# SA3_SS_SA_UL_0_SA_UL_UPDATES_40901000h register map
Vendor: Texas Instruments
Peripheral module from a debugger description file (folder AM275x).
Registers are 32-bit, write-only, reset 0x0 unless marked. A register's access mark holds for its fields unless they carry their own. Offsets are as the file gives them; lines under a group give offsets from that group; [hi:lo] are bit positions; {n}, {i} and the like mark numbered series; 'fields as' and 'values as' point back to an identical list; <NAME> marks a mode.

## sa_ul_updates
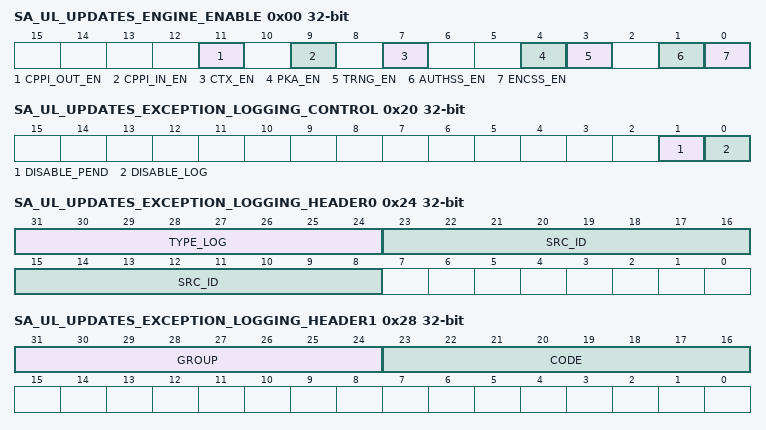
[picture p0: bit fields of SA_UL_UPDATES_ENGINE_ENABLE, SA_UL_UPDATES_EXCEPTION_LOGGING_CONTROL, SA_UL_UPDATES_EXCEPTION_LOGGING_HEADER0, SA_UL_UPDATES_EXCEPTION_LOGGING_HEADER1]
0x00 SA_UL_UPDATES_ENGINE_ENABLE rw — This register controls the enable of each crypto engine
  [11] CPPI_OUT_EN — cppi out enable Reset Source: rst_mod_g_rst_n
  [9] CPPI_IN_EN — cppi in enable Reset Source: rst_mod_g_rst_n
  [7] CTX_EN — ctxcach enable Reset Source: rst_mod_g_rst_n
  [4] PKA_EN — pka enable Reset Source: rst_mod_g_rst_n
  [3] TRNG_EN — trng enable Reset Source: rst_mod_g_rst_n
  [1] AUTHSS_EN — authss enable Reset Source: rst_mod_g_rst_n
  [0] ENCSS_EN — encss enable Reset Source: rst_mod_g_rst_n
0x10 SA_UL_UPDATES_SCPTR_PROMOTE_LOW_RANGE_L rw — This register contains bit 31:0 of the SCPTR lower limit for promotion check
  [31:0] BIT_31_0 — The lower 32-bits of SCPTR lower limit Reset Source: rst_mod_g_rst_n
0x14 SA_UL_UPDATES_SCPTR_PROMOTE_LOW_RANGE_H rw — This register contains bit 47:32 of the SCPTR lower limit for promotion check
  [15:0] BIT_47_32 — The upper 16-bits of SCPTR lower limit Reset Source: rst_mod_g_rst_n
0x18 SA_UL_UPDATES_SCPTR_PROMOTE_HI_RANGE_L rw — This register contains bit 31:0 of the SCPTR upper limit for promotion check
  [31:0] BIT_31_0 — The lower 32-bits of SCPTR upper limit Reset Source: rst_mod_g_rst_n
0x1C SA_UL_UPDATES_SCPTR_PROMOTE_HI_RANGE_H rw — This register contains bit 47:32 of the SCPTR upper limit for promotion check
  [15:0] BIT_47_32 — The upper 16-bits of SCPTR upper limit Reset Source: rst_mod_g_rst_n
0x20 SA_UL_UPDATES_EXCEPTION_LOGGING_CONTROL rw — The Exception Logging Control Register controls the exception logging.
  [1] DISABLE_PEND — Disables logging pending when set. Reset Source: rst_mod_g_rst_n
  [0] DISABLE_LOG — Disables logging when set. Reset Source: rst_mod_g_rst_n
0x24 SA_UL_UPDATES_EXCEPTION_LOGGING_HEADER0 ro — The Exception Logging Header 0 Register contains the first word of the header.
  [31:24] TYPE_LOG — Type. Reset Source: rst_mod_g_rst_n
  [23:8] SRC_ID — Source ID. Reset Source: rst_mod_g_rst_n
0x28 SA_UL_UPDATES_EXCEPTION_LOGGING_HEADER1 ro — The Exception Logging Header 1 Register contains the second word of the header.
  [31:24] GROUP — Group. Reset Source: rst_mod_g_rst_n
  [23:16] CODE — Code. Reset Source: rst_mod_g_rst_n
0x2C SA_UL_UPDATES_EXCEPTION_LOGGING_DATA0 ro — The Exception Logging Data 0 Register contains the first word of the data.
  [31:0] ADDR_L — SCPTR lower 32 bits. Reset Source: rst_mod_g_rst_n
0x30 SA_UL_UPDATES_EXCEPTION_LOGGING_DATA1 ro — The Exception Logging Data 1 Register contains the second word of the data.
  [15:0] ADDR_H — SCPTR upper 16 bits. Reset Source: rst_mod_g_rst_n
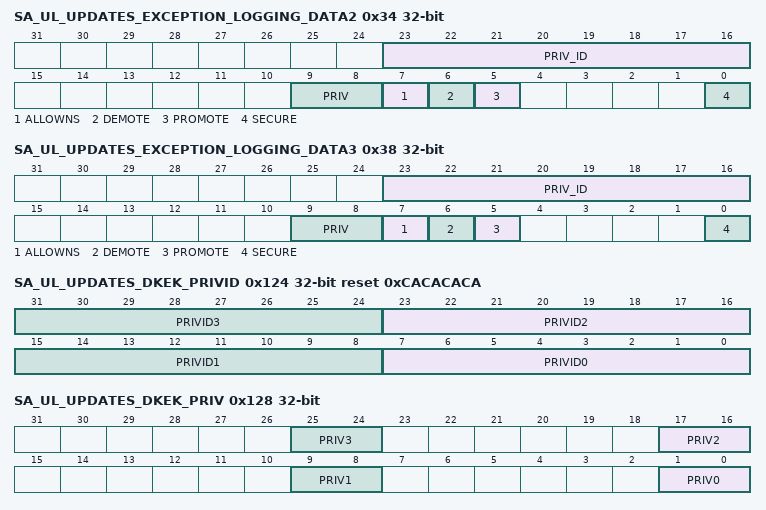
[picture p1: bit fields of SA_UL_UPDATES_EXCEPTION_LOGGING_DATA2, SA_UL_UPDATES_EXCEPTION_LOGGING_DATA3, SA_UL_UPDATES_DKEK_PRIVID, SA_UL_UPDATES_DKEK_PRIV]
0x34 SA_UL_UPDATES_EXCEPTION_LOGGING_DATA2 ro — The Exception Logging Data 2 Register contains the third word of the data.
  [23:16] PRIV_ID — Ingress Packet Priv ID attribute. Reset Source: rst_mod_g_rst_n
  [9:8] PRIV — Ingress Packet Priv attribute. Reset Source: rst_mod_g_rst_n
  [7] ALLOWNS — Ingress Packet AllowNS attribute. Reset Source: rst_mod_g_rst_n
  [6] DEMOTE — Ingress Packet Demote attribute. Reset Source: rst_mod_g_rst_n
  [5] PROMOTE — Ingress Packet Promote attribute. Reset Source: rst_mod_g_rst_n
  [0] SECURE — Ingress Packet Secure attribute. Reset Source: rst_mod_g_rst_n
0x38 SA_UL_UPDATES_EXCEPTION_LOGGING_DATA3 ro — The Exception Logging Data 3 Register contains the fourth word of the data.
  [23:16] PRIV_ID — Context Priv ID. Reset Source: rst_mod_g_rst_n
  [9:8] PRIV — Context Priv. Reset Source: rst_mod_g_rst_n
  [7] ALLOWNS — Context AllowNS. Reset Source: rst_mod_g_rst_n
  [6] DEMOTE — Context Demote. Reset Source: rst_mod_g_rst_n
  [5] PROMOTE — Context Promote. Reset Source: rst_mod_g_rst_n
  [0] SECURE — Context Secure. Reset Source: rst_mod_g_rst_n
0x40 SA_UL_UPDATES_EXCEPTION_PEND_SET access not given — The Exception Logging Pending Set Register allows to set the pend signal.
  [0] PEND_SET — Write a 1 to set the exception pend signal. Reset Source: rst_mod_g_rst_n (access R/W1TS)
0x44 SA_UL_UPDATES_EXCEPTION_PEND_CLEAR access not given — The Exception Logging Pending Clear Register allows to clear the pend signal.
  [0] PEND_CLR — Write a 1 to clear the exception pend signal. Reset Source: rst_mod_g_rst_n (access R/W1TC)
0x50 SA_UL_UPDATES_TRNG_INTR_SET access not given — The TRNG Interrupt Set Register allows to set trng_intr output for testing purpose.
  [0] TRNG_SET — Write a 1 to set the interrupt. Reset Source: rst_mod_g_rst_n (access R/W1TS)
0x54 SA_UL_UPDATES_TRNG_INTR_CLEAR access not given — The TRNG Interrupt Clear Register allows to clear the trng_intr output for testing purpose.
  [0] TRNG_CLR — Write a 1 to clear the exception pend signal. Reset Source: rst_mod_g_rst_n (access R/W1TC)
0x60 SA_UL_UPDATES_PKA_INTR_SET access not given — The PKA Interrupt Set Register allows to set pka_intr output for testing purpose.
  [0] PKA_SET — Write a 1 to set the interrupt. Reset Source: rst_mod_g_rst_n (access R/W1TS)
0x64 SA_UL_UPDATES_PKA_INTR_CLEAR access not given — The PKA Interrupt Clear Register allows to clear the pka_intr output for testing purpose.
  [0] PKA_CLR — Write a 1 to clear the exception pend signal. Reset Source: rst_mod_g_rst_n (access R/W1TC)
{0x100+4i} SA_UL_UPDATES_KEK_{i} (i=0..7) — DKEK key is used as AES key only when Use_DKEK bit in the context is set to 1.
  [31:0] KEYS — bit {32i+31}:{32i} of DKEK keys Reset Source: rst_mod_g_rst_n
0x120 SA_UL_UPDATES_KEK_LOCK — This register can be written to lock and prevent further write access to kek_0 - kek_7 registers.
  [0] LOCK — The lock bit is only writable once. Once set, the kek registers cannot be reprogrammed without resetting the device Reset Source: rst_mod_g_rst_n
0x124 SA_UL_UPDATES_DKEK_PRIVID reset 0xCACACACA — Only packet with privid matching any one of the programmed four privid values in this write-only register is allowed to use the encryption engine with D-KEK key. This feature is only enabled if the Use_DKEK bit in the context is set.
  [8n+7:8n] PRIVID{n} (n=0..3) — slot{n} of privid that is allowed to use D-KEK Reset Source: rst_mod_g_rst_n
0x128 SA_UL_UPDATES_DKEK_PRIV — Only packet with priv matching any one of the programmed four priv values in this write-only register will be allowed to use the encryption engine with D-KEK key. This feature is only enabled if the Use_DKEK bit in the context is set.
  [8n+1:8n] PRIV{n} (n=0..3) — slot{n} of priv that is allowed to use D-KEK Reset Source: rst_mod_g_rst_n
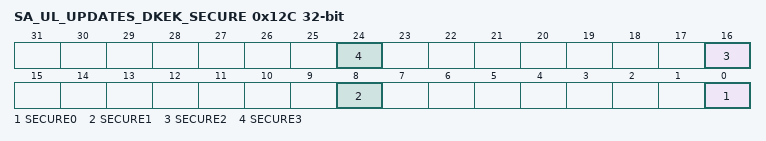
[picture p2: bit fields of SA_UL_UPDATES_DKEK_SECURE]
0x12C SA_UL_UPDATES_DKEK_SECURE — Only packet with secure matching any one of the programmed four secure values in this write-only register will be allowed to use the encryption engine with D-KEK key. This feature is only enabled if the Use_DKEK bit in the context is set.
  [8n] SECURE{n} (n=0..3) — slot{n} of secure that is allowed to use D-KEK Reset Source: rst_mod_g_rst_n
